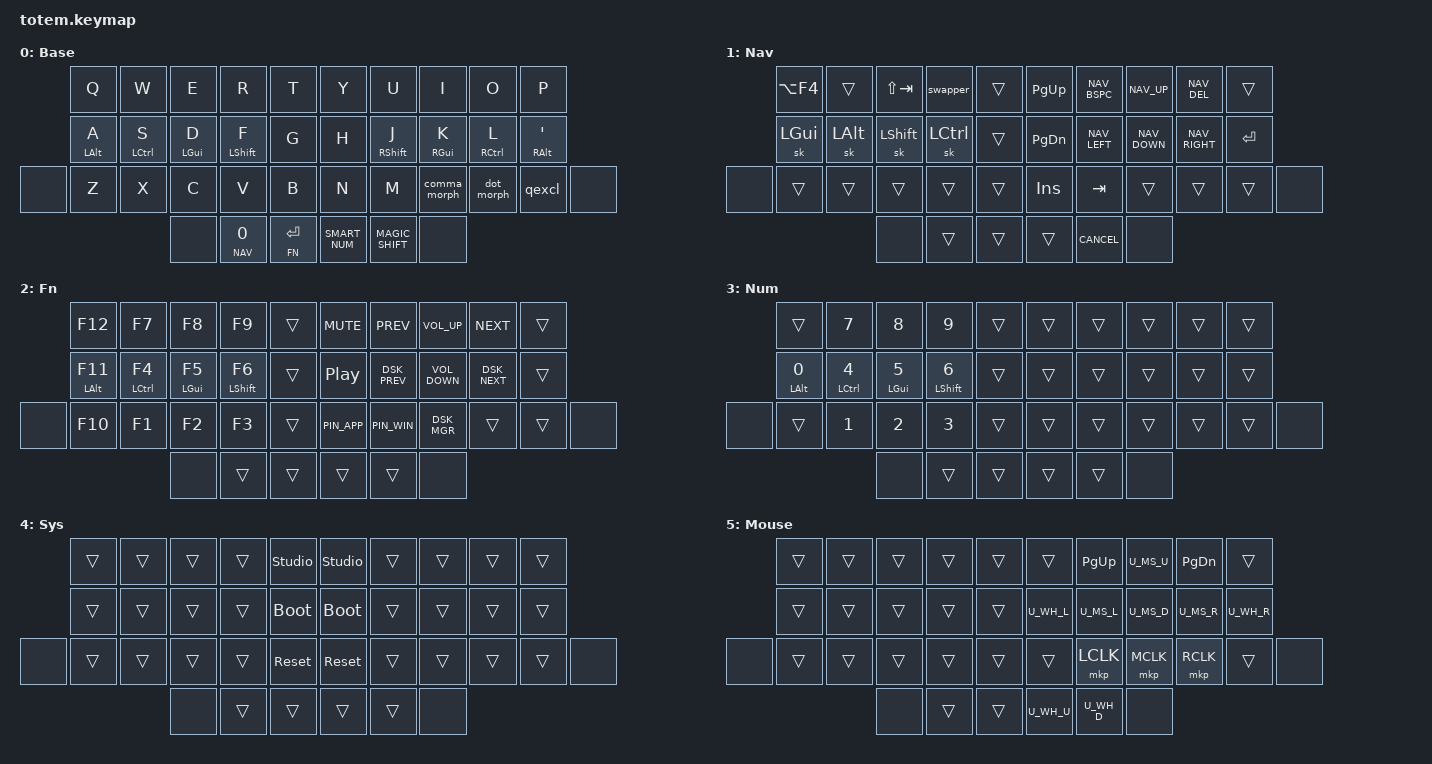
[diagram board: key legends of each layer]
// TOTEM 38-key ZMK keymap — urob's full config adapted for QWERTY

#include <behaviors.dtsi>
#include <behaviors/num_word.dtsi> // Requires zmk-auto-layer module.
#include <behaviors/unicode.dtsi> // Requires zmk-unicode module.
#include <zmk-helpers/helper.h>   // Requires zmk-helpers module.
#include <zmk-helpers/key-labels/totem.h> // Requires zmk-helpers module.
#include <dt-bindings/zmk/keys.h>

#define DEF 0
#define NAV 1
#define FN 2
#define NUM 3
#define SYS 4
#define MOUSE 5

#define NONE &none
#define ___ &trans
#define STUDIO &studio_unlock

#include "behaviors.dtsi" // Must precede combos.dtsi (defines HRM-combo hack).
#include "combos.dtsi"    // Must be sourced after HRM-combo hack.
#include "leader.dtsi"
#include "mouse.dtsi"

/* Keymap */

ZMK_CONDITIONAL_LAYER(sys, FN NUM, SYS) // FN + NUM --> SYS.

ZMK_LAYER(Base,
                &kp Q         &kp W         &kp E         &kp R         &kp T           &kp Y         &kp U         &kp I         &kp O         &kp P
                &hml LALT A   &hml LCTRL S  &hml LGUI D   &hml LSHFT F  &kp G           &kp H         &hmr RSHFT J  &hmr RGUI K   &hmr RCTRL L  &hmr RALT SQT
    NONE        &kp Z         &kp X         &kp C         &kp V         &kp B           &kp N         &kp M         &comma_morph  &dot_morph    &qexcl        NONE
                                            NONE          &lt_spc NAV 0 &lt FN RET      SMART_NUM     MAGIC_SHIFT   NONE
)

ZMK_LAYER(Nav,
                &kp LA(F4)    ___           &kp LS(TAB)   &swapper      ___             &kp PG_UP     NAV_BSPC      NAV_UP        NAV_DEL       ___
                &sk LGUI      &sk LALT      &sk LSHFT     &sk LCTRL     ___             &kp PG_DN     NAV_LEFT      NAV_DOWN      NAV_RIGHT     &kp RET
     NONE       ___           ___           ___           ___           ___             &kp INS       &kp TAB       ___           ___           ___           NONE
                                            NONE          ___           ___             ___           CANCEL        NONE
)

ZMK_LAYER(Fn,
                &kp F12       &kp F7        &kp F8        &kp F9        ___             &kp C_MUTE    &kp C_PREV    &kp C_VOL_UP  &kp C_NEXT    ___
                &hml LALT F11 &hml LCTRL F4 &hml LGUI F5  &hml LSHFT F6 ___             &kp C_PP      DSK_PREV      VOL_DOWN      DSK_NEXT      ___
    NONE        &kp F10       &kp F1        &kp F2        &kp F3        ___             PIN_APP       PIN_WIN       DSK_MGR       ___           ___           NONE
                                            NONE          ___           ___             ___           ___           NONE
)

ZMK_LAYER(Num,
                ___           &kp N7        &kp N8        &kp N9        ___             ___           ___           ___           ___           ___
                &hml LALT N0  &hml LCTRL N4 &hml LGUI N5  &hml LSHFT N6 ___             ___           ___           ___           ___           ___
    NONE        ___           &kp N1        &kp N2        &kp N3        ___             ___           ___           ___           ___           ___           NONE
                                            NONE          ___           ___             ___           ___           NONE
)

ZMK_LAYER(Sys,
                ___           ___           ___           ___           STUDIO          STUDIO        ___           ___           ___           ___
                ___           ___           ___           ___           &bootloader     &bootloader   ___           ___           ___           ___
    NONE        ___           ___           ___           ___           &sys_reset      &sys_reset    ___           ___           ___           ___           NONE
                                            NONE          ___           ___             ___           ___           NONE
)

ZMK_LAYER(Mouse,
                ___           ___           ___           ___           ___             ___           &kp PG_UP     U_MS_U        &kp PG_DN     ___
                ___           ___           ___           ___           ___             U_WH_L        U_MS_L        U_MS_D        U_MS_R        U_WH_R
    NONE        ___           ___           ___           ___           ___             ___           &mkp LCLK     &mkp MCLK     &mkp RCLK     ___           NONE
                                            NONE          ___           ___             U_WH_U        U_WH_D        NONE
)

/* vim: set ft=c tw=146: */
